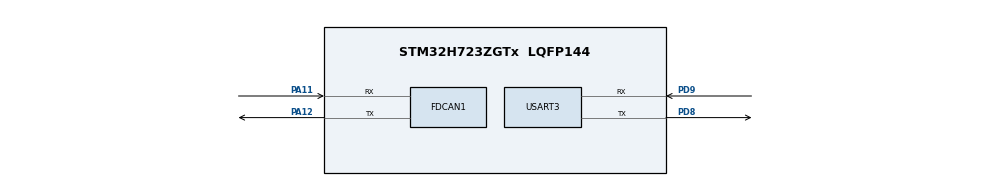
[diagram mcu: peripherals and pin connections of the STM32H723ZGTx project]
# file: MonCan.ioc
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CORTEX_M7.CPU_DCache=Enabled
CORTEX_M7.CPU_ICache=Enabled
FDCAN1.Mode=FDCAN_MODE_INTERNAL_LOOPBACK
FDCAN1.RxFifo0ElmtsNbr=1
FDCAN1.TxFifoQueueElmtsNbr=1
Mcu.Family=STM32H7
Mcu.Name=STM32H723ZGTx
Mcu.Package=LQFP144
NVIC.PriorityGroup=NVIC_PRIORITYGROUP_4
NVIC.TIM6_DAC_IRQn=true\:15\:0\:false\:false\:true\:false\:false\:true
NVIC.TimeBase=TIM6_DAC_IRQn
NVIC.TimeBaseIP=TIM6
PA11.Mode=FDCAN_Activate
PA11.Signal=FDCAN1_RX
PA12.Mode=FDCAN_Activate
PA12.Signal=FDCAN1_TX
PD8.Mode=Asynchronous
PD8.Signal=USART3_TX
PD9.Mode=Asynchronous
PD9.Signal=USART3_RX
PH0-OSC_IN.Mode=HSE-External-Clock-Source
PH0-OSC_IN.Signal=RCC_OSC_IN
ProjectManager.HeapSize=0x200
ProjectManager.StackSize=0x400
ProjectManager.TargetToolchain=STM32CubeIDE
RCC.ADCFreq_Value=16125000
RCC.APB1Freq_Value=45000000
RCC.APB2Freq_Value=45000000
RCC.APB3Freq_Value=45000000
RCC.APB4Freq_Value=45000000
RCC.CortexFreq_Value=180000000
RCC.D1CPRE=RCC_SYSCLK_DIV2
RCC.D1PPRE=RCC_APB3_DIV2
RCC.D2PPRE1=RCC_APB1_DIV2
RCC.D2PPRE2=RCC_APB2_DIV2
RCC.D3PPRE=RCC_APB4_DIV2
RCC.DIVM1=1
RCC.DIVM3=16
RCC.DIVN1=45
RCC.DIVP1=1
RCC.DIVQ1=5
RCC.HCLKFreq_Value=90000000
RCC.HPRE=RCC_HCLK_DIV2
RCC.HSE_VALUE=8000000
RCC.PLL3_VCI_Range-AdvancedSettings=RCC_PLL3VCIRANGE_3
RCC.PLLFRACN=0
RCC.PLLSourceVirtual=RCC_PLLSOURCE_HSE
RCC.SYSCLKFreq_VALUE=360000000
RCC.SYSCLKSource=RCC_SYSCLKSOURCE_PLLCLK
RCC.USBFreq_Value=72000000
STMicroelectronics.X-CUBE-AZRTOS-H7.2.0.0.TX_APP_MEM_POOL_SIZE=2 * 1024
STMicroelectronics.X-CUBE-AZRTOS-H7.2.0.0.TX_DISABLE_PREEMPTION_THRESHOLD=0
STMicroelectronics.X-CUBE-AZRTOS-H7.2.0.0.ThreadXCcRTOSJjThreadXJjCore=true
STMicroelectronics.X-CUBE-AZRTOS-H7.2.0.0_IsAnAzureRtosMw=true
USART3.VirtualMode-Asynchronous=VM_ASYNC
VP_STMicroelectronics.X-CUBE-AZRTOS-H7_VS_RTOSJjThreadX_6.1.7_2.0.0.Mode=RTOSJjThreadX
VP_SYS_VS_tim6.Mode=TIM6
board=NUCLEO-H723ZG

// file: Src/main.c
/* USER CODE BEGIN Header */
/**
  ******************************************************************************
  * @file           : main.c
  * @brief          : Main program body
  ******************************************************************************
  * @attention
  *
  * <h2><center>&copy; Copyright (c) 2021 STMicroelectronics.
  * All rights reserved.</center></h2>
  *
  * This software component is licensed by ST under Ultimate Liberty license
  * SLA0044, the "License"; You may not use this file except in compliance with
  * the License. You may obtain a copy of the License at:
  *                             www.st.com/SLA0044
  *
  ******************************************************************************
  */
/* USER CODE END Header */
#include "main.h"
#include "app_threadx.h"

/* USER CODE BEGIN Includes */
#include "demo.h"
#include "logger.h"
#include "vcp_th.h"
/* USER CODE END Includes */

FDCAN_HandleTypeDef hfdcan1;

UART_HandleTypeDef huart3;

void SystemClock_Config(void);
static void MX_GPIO_Init(void);
static void MX_USART3_UART_Init(void);
static void MX_FDCAN1_Init(void);

int main(void)
{

  /* Enable I-Cache---------------------------------------------------------*/
  SCB_EnableICache();

  /* Enable D-Cache---------------------------------------------------------*/
  SCB_EnableDCache();

  /* MCU Configuration--------------------------------------------------------*/

  /* Reset of all peripherals, Initializes the Flash interface and the Systick. */
  HAL_Init();

  /* Configure the system clock */
  SystemClock_Config();

  /* Initialize all configured peripherals */
  MX_GPIO_Init();
  MX_USART3_UART_Init();
  MX_FDCAN1_Init();
  /* USER CODE BEGIN 2 */
  vcp_init(&huart3);
  log_init();
  demo_init(&hfdcan1);
  /* USER CODE END 2 */

  MX_ThreadX_Init();
  /* Infinite loop */
  while (1)
  {

  }
}

void SystemClock_Config(void)
{
  RCC_OscInitTypeDef RCC_OscInitStruct = {0};
  RCC_ClkInitTypeDef RCC_ClkInitStruct = {0};

  /** Supply configuration update enable
  */
  HAL_PWREx_ConfigSupply(PWR_LDO_SUPPLY);
  /** Configure the main internal regulator output voltage
  */
  __HAL_PWR_VOLTAGESCALING_CONFIG(PWR_REGULATOR_VOLTAGE_SCALE2);

  while(!__HAL_PWR_GET_FLAG(PWR_FLAG_VOSRDY)) {}
  /** Initializes the RCC Oscillators according to the specified parameters
  * in the RCC_OscInitTypeDef structure.
  */
  RCC_OscInitStruct.OscillatorType = RCC_OSCILLATORTYPE_HSE;
  RCC_OscInitStruct.HSEState = RCC_HSE_BYPASS;
  RCC_OscInitStruct.PLL.PLLState = RCC_PLL_ON;
  RCC_OscInitStruct.PLL.PLLSource = RCC_PLLSOURCE_HSE;
  RCC_OscInitStruct.PLL.PLLM = 1;
  RCC_OscInitStruct.PLL.PLLN = 45;
  RCC_OscInitStruct.PLL.PLLP = 1;
  RCC_OscInitStruct.PLL.PLLQ = 5;
  RCC_OscInitStruct.PLL.PLLR = 2;
  RCC_OscInitStruct.PLL.PLLRGE = RCC_PLL1VCIRANGE_3;
  RCC_OscInitStruct.PLL.PLLVCOSEL = RCC_PLL1VCOWIDE;
  RCC_OscInitStruct.PLL.PLLFRACN = 0;
  if (HAL_RCC_OscConfig(&RCC_OscInitStruct) != HAL_OK)
  {
    Error_Handler();
  }
  /** Initializes the CPU, AHB and APB buses clocks
  */
  RCC_ClkInitStruct.ClockType = RCC_CLOCKTYPE_HCLK|RCC_CLOCKTYPE_SYSCLK
                              |RCC_CLOCKTYPE_PCLK1|RCC_CLOCKTYPE_PCLK2
                              |RCC_CLOCKTYPE_D3PCLK1|RCC_CLOCKTYPE_D1PCLK1;
  RCC_ClkInitStruct.SYSCLKSource = RCC_SYSCLKSOURCE_PLLCLK;
  RCC_ClkInitStruct.SYSCLKDivider = RCC_SYSCLK_DIV2;
  RCC_ClkInitStruct.AHBCLKDivider = RCC_HCLK_DIV2;
  RCC_ClkInitStruct.APB3CLKDivider = RCC_APB3_DIV2;
  RCC_ClkInitStruct.APB1CLKDivider = RCC_APB1_DIV2;
  RCC_ClkInitStruct.APB2CLKDivider = RCC_APB2_DIV2;
  RCC_ClkInitStruct.APB4CLKDivider = RCC_APB4_DIV2;

  if (HAL_RCC_ClockConfig(&RCC_ClkInitStruct, FLASH_LATENCY_1) != HAL_OK)
  {
    Error_Handler();
  }
}

static void MX_FDCAN1_Init(void)
{

  hfdcan1.Instance = FDCAN1;
  hfdcan1.Init.FrameFormat = FDCAN_FRAME_CLASSIC;
  hfdcan1.Init.Mode = FDCAN_MODE_INTERNAL_LOOPBACK;
  hfdcan1.Init.AutoRetransmission = DISABLE;
  hfdcan1.Init.TransmitPause = DISABLE;
  hfdcan1.Init.ProtocolException = DISABLE;
  hfdcan1.Init.NominalPrescaler = 1;
  hfdcan1.Init.NominalSyncJumpWidth = 1;
  hfdcan1.Init.NominalTimeSeg1 = 2;
  hfdcan1.Init.NominalTimeSeg2 = 2;
  hfdcan1.Init.DataPrescaler = 1;
  hfdcan1.Init.DataSyncJumpWidth = 1;
  hfdcan1.Init.DataTimeSeg1 = 1;
  hfdcan1.Init.DataTimeSeg2 = 1;
  hfdcan1.Init.MessageRAMOffset = 0;
  hfdcan1.Init.StdFiltersNbr = 0;
  hfdcan1.Init.ExtFiltersNbr = 0;
  hfdcan1.Init.RxFifo0ElmtsNbr = 1;
  hfdcan1.Init.RxFifo0ElmtSize = FDCAN_DATA_BYTES_8;
  hfdcan1.Init.RxFifo1ElmtsNbr = 0;
  hfdcan1.Init.RxFifo1ElmtSize = FDCAN_DATA_BYTES_8;
  hfdcan1.Init.RxBuffersNbr = 0;
  hfdcan1.Init.RxBufferSize = FDCAN_DATA_BYTES_8;
  hfdcan1.Init.TxEventsNbr = 0;
  hfdcan1.Init.TxBuffersNbr = 0;
  hfdcan1.Init.TxFifoQueueElmtsNbr = 1;
  hfdcan1.Init.TxFifoQueueMode = FDCAN_TX_FIFO_OPERATION;
  hfdcan1.Init.TxElmtSize = FDCAN_DATA_BYTES_8;
  if (HAL_FDCAN_Init(&hfdcan1) != HAL_OK)
  {
    Error_Handler();
  }

}

static void MX_USART3_UART_Init(void)
{

  huart3.Instance = USART3;
  huart3.Init.BaudRate = 115200;
  huart3.Init.WordLength = UART_WORDLENGTH_8B;
  huart3.Init.StopBits = UART_STOPBITS_1;
  huart3.Init.Parity = UART_PARITY_NONE;
  huart3.Init.Mode = UART_MODE_TX_RX;
  huart3.Init.HwFlowCtl = UART_HWCONTROL_NONE;
  huart3.Init.OverSampling = UART_OVERSAMPLING_16;
  huart3.Init.OneBitSampling = UART_ONE_BIT_SAMPLE_DISABLE;
  huart3.Init.ClockPrescaler = UART_PRESCALER_DIV1;
  huart3.AdvancedInit.AdvFeatureInit = UART_ADVFEATURE_NO_INIT;
  if (HAL_UART_Init(&huart3) != HAL_OK)
  {
    Error_Handler();
  }
  if (HAL_UARTEx_SetTxFifoThreshold(&huart3, UART_TXFIFO_THRESHOLD_1_8) != HAL_OK)
  {
    Error_Handler();
  }
  if (HAL_UARTEx_SetRxFifoThreshold(&huart3, UART_RXFIFO_THRESHOLD_1_8) != HAL_OK)
  {
    Error_Handler();
  }
  if (HAL_UARTEx_DisableFifoMode(&huart3) != HAL_OK)
  {
    Error_Handler();
  }

}

static void MX_GPIO_Init(void)
{

  /* GPIO Ports Clock Enable */
  __HAL_RCC_GPIOH_CLK_ENABLE();
  __HAL_RCC_GPIOD_CLK_ENABLE();
  __HAL_RCC_GPIOA_CLK_ENABLE();

}

void HAL_TIM_PeriodElapsedCallback(TIM_HandleTypeDef *htim)
{
  if (htim->Instance == TIM6) {
    HAL_IncTick();
  }
}

void Error_Handler(void)
{
  __disable_irq();
  while (1)
  {
  }
}

/************************ (C) COPYRIGHT STMicroelectronics *****END OF FILE****/
